# nrf7140_wificore register map
Vendor: Nordic Semiconductor; Series: nRF71; File version: 1
Registers are 32-bit, read-write, reset 0x0 unless marked. A register's access mark holds for its fields unless they carry their own. Offsets are from the block's base; [hi:lo] are bit positions; lines under a group give offsets from that group; {n}, {i} and the like mark numbered series; 'fields as' and 'values as' point back to an identical list.

## ANTSWC — Antenna switch controller
Base 0x4800D000
0x400 ERRORSTATUS group — Unspecified
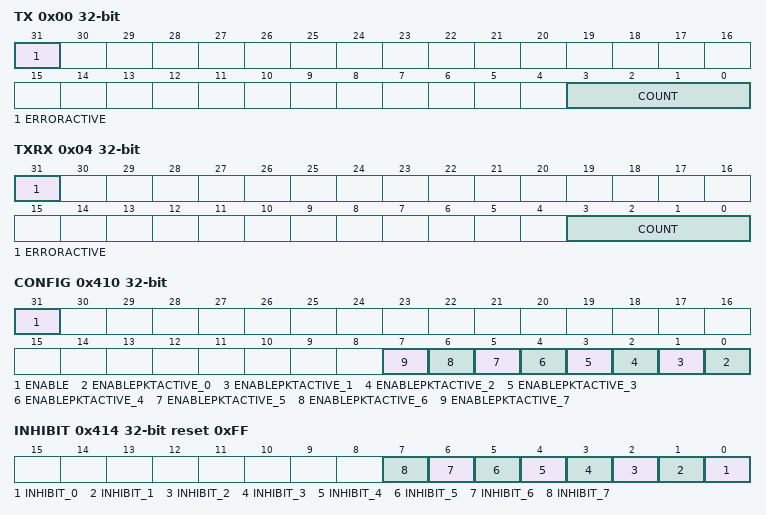
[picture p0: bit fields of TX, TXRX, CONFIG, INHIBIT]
  0x00 TX — Concurrent TX error condition
    [31] ERRORACTIVE ro — Concurrent TX error condition is active
    [3:0] COUNT — Count of concurrent TX error conditions detected
  0x04 TXRX — Concurrent TX-RX error condition
    [31] ERRORACTIVE ro — Concurrent TX-RX error condition is active
    [3:0] COUNT — Count of concurrent TX-RX error conditions detected
  0x08 ERRORPORT — Indicates which ports are in error
    [7:0] ERRORPORT — Bitfield indicating the ports in error during the last error condition.
0x410 CONFIG — Antenna switch controller enable / software reset
  [31] ENABLE — Enable antenna switch module.
    0=Disable (Antenna Switch Controller disabled - all outputs held low); 1=Enable (Antenna Switch Controller enabled)
  [n] ENABLEPKTACTIVE_{n} (n=0..7) — Bitfield indicating whether ANTSWC listens to PktActive on radio port i.
    0=Ignore PktActive on the corresponding radio port; 1=Respect (Use PktActive on the corresponding radio port for antenna switch selection)
0x414 INHIBIT reset 0xFF
  [all] fields
    0=Inhibit connection of antenna to the corresponding radio; 1=Enable antenna to be connected to the corresponding radio
  [n] INHIBIT_{n} (n=0..7) — Bitfield of 8 separate bits indicating whether connection of the antenna to radio on radio port i is enabled or inhibited.
0x500 OVERRIDE group — Unspecified
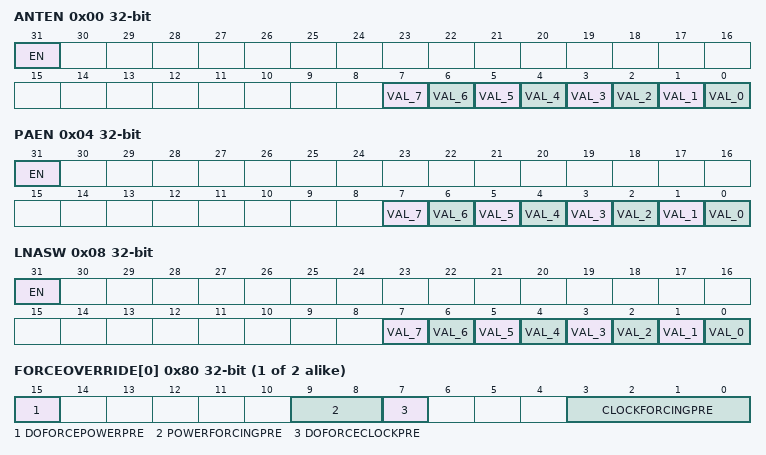
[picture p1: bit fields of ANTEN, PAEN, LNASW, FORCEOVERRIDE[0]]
  0x00 ANTEN — Override antenna switch (AntSw) output signals
    [31] EN
      0=Disable (Override is disabled); 1=Enable (Override is enabled)
    [n] VAL_{n} (n=0..7) — Override configuration for AntSw. Note only one bit should be set and AntSw will be set to the encoded value of the position of the set bit. Where multiple bits are set the AntSw signal value is set to 0
      0=Clear (Antenna port not selected); 1=Set (Antenna port selected)
  0x04 PAEN — Override power amplifier enable (PaEn) output signals
    [31] EN
      values as OVERRIDE.ANTEN.EN
    [n] VAL_{n} (n=0..7) — Override value for the signal PAEn[i]
      0=Clear the corresponding bit in PAEn; 1=Set (Assert the corresponding bit in PAEn)
  0x08 LNASW — Override shared LNA switch (LnaSw) output signals
    [31] EN
      values as OVERRIDE.ANTEN.EN
    [n] VAL_{n} (n=0..7) — Override value for the signal LnaSw[i]
      0=Clear the corresponding bit in LnaSw; 1=Set (Assert the corresponding bit in LnaSw)
0xF00 PCGCSLAVE group — Unspecified
  {0x0+4j} PENALTY[{j}] (j=0..1) reset 0xFFFFFFFC — Description collection: Penalty level for power/clock pair n. When FULL_PCP_ZERO feature is not supported, PENALTY[0] address overlaps the PENALTY0 address and register description for PENALTY[0] is not valid.
    [1:0] PENALTY — Penalty level
  0x00 PENALTY0 (alternate view of PENALTY[*]) — Penalty level for power/clock pair 0. The register description is valid only when FULL_PCP_ZERO feature is not supported
    [1:0] PENALTY ro — Penalty level
  {0x80+4j} FORCEOVERRIDE[{j}] (j=0..1) — Description collection: Force override of power/clock pair n.
    [15] DOFORCEPOWERPRE, [9:8] POWERFORCINGPRE, [7] DOFORCECLOCKPRE, [3:0] CLOCKFORCINGPRE

## RESETINFO
Base 0x48010000; alternate view of LRCCONF010
0x4A0 RESETREAS group — Unspecified
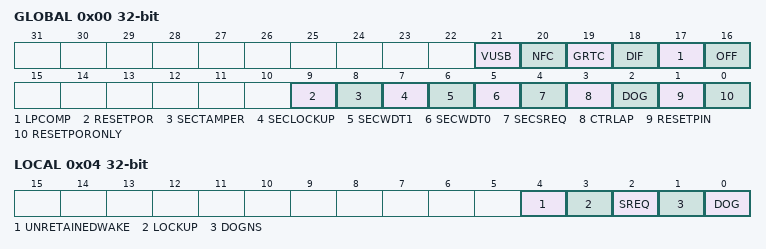
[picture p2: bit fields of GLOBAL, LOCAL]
  0x00 GLOBAL — Global reset reason.
    [all] fields
      0=NotDetected; 1=Detected
    [21] VUSB — Reset after wakeup from System OFF mode due to VBUS rising into valid range.
    [20] NFC — Reset due to wakeup from System OFF mode when wakeup is triggered by NFC field detection in sense mode.
    [19] GRTC — Reset due to wakeup from System OFF mode when wakeup is triggered by GRTC interrupt.
    [18] DIF — Reset due to wakeup from System OFF mode when wakeup is triggered by entering the debug interface mode.
    [17] LPCOMP — Reset due to wakeup from System OFF mode when wakeup is triggered by LPCOMP (Low Power Comparator).
    [16] OFF — Reset due to wakeup from System OFF mode when wakeup is triggered by DETECT signal from GPIO.
    [9] RESETPOR — Reset from power on reset (reset reason other than POR or BOR).
    [8] SECTAMPER — Reset due to secure domain tamper detected
    [7] SECLOCKUP — Reset due to secure domain lockup.
    [6] SECWDT1 — Reset due to the second instance of watchdog timer in secure domain detected.
    [5] SECWDT0 — Reset due to the first instance of watchdog timer in secure domain detected.
    [4] SECSREQ — Reset due to secure domain system reset request.
    [3] CTRLAP — Reset from CTRL-AP detected.
    [2] DOG — Reset from the SysCtrl watchdog timer detected.
    [1] RESETPIN — Reset from pin reset detected.
    [0] RESETPORONLY — Reset from power on reset (reset reason POR or BOR).
  0x04 LOCAL — Local reset reason.
    [4] UNRETAINEDWAKE — Reset due to wake from unretained state.
    [3] LOCKUP — Reset from local CPU lockup detected
      0=NotDetected; 1=Detected
    [2] SREQ — Reset from the local soft reset request detected.
      0=NotDetected; 1=Detected
    [1] DOGNS — Reset from the local non-secure watchdog timer detected
      0=NotDetected; 1=Detected
    [0] DOG — Reset from the local watchdog timer detected
      0=NotDetected; 1=Detected
0x4A8 ERROR group — Unspecified
  0x00 STATUS — Reset error status.
    [3:0] ERRORSTATUS
  0x04 ADDRESS — Reset error address.
    [31:0] ERRORADDRESS
0x4C0 RESTOREVALID — Valid restore image is present in RAM.
  [0] RESTOREVALID
    0=NotPreset (Not present); 1=Present
0x4C4 MASKLOCKUP — Mask CPU lockup signal.
  [0] MASK — Mask lockup signal
    0=NotMask (Do not mask lockup signal); 1=Mask lockup signal
